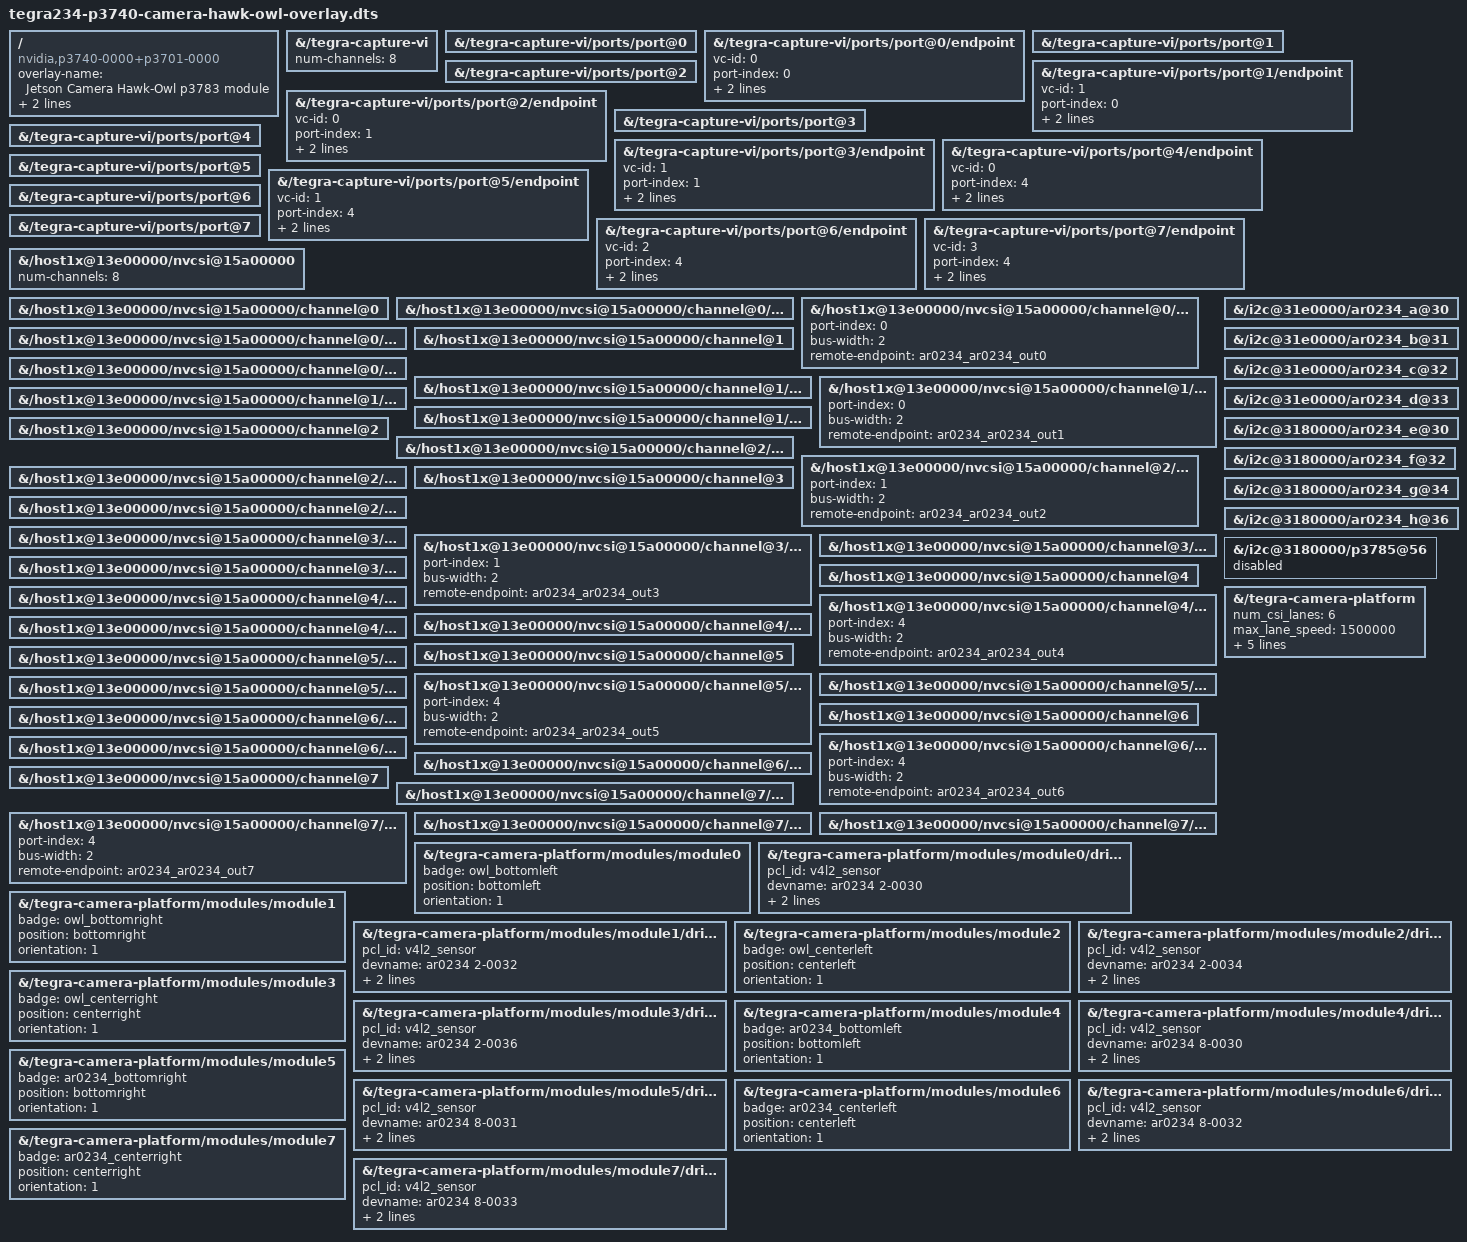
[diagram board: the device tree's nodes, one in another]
/*
 * Copyright (c) 2023, NVIDIA CORPORATION.  All rights reserved.
 *
 * This program is free software; you can redistribute it and/or modify it
 * under the terms and conditions of the GNU General Public License,
 * version 2, as published by the Free Software Foundation.
 *
 * This program is distributed in the hope it will be useful, but WITHOUT
 * ANY WARRANTY; without even the implied warranty of MERCHANTABILITY or
 * FITNESS FOR A PARTICULAR PURPOSE.  See the GNU General Public License for
 * more details.
 *
 * You should have received a copy of the GNU General Public License
 * along with this program.  If not, see <http://www.gnu.org/licenses/>.
 */

/*
 * Device-tree overlay for Hawk & Owl.
 */

/dts-v1/;
/plugin/;

/ {
	overlay-name = "Jetson Camera Hawk-Owl p3783 module";
	jetson-header-name = "Jetson 122pin CSI Connector";
	compatible = "nvidia,p3740-0000+p3701-0000", "nvidia,p3740-0002-b01+p3701-0002";

	/* VI number of channels */
	fragment@0 {
		target-path = "/tegra-capture-vi";
		board_config {
			sw-modules = "kernel";
		};
		__overlay__ {
			num-channels=<8>;
		};
	};

	fragment@1 {
		target-path = "/tegra-capture-vi/ports/port@0";
		board_config {
			sw-modules = "kernel";
		};
		__overlay__ {
			status = "okay";
		};
	};
	fragment@2 {
		target-path = "/tegra-capture-vi/ports/port@0/endpoint";
		board_config {
			sw-modules = "kernel";
		};
		__overlay__ {
			status = "okay";
			vc-id = <0>;
			port-index = <0>;
			bus-width = <2>;
			remote-endpoint = <&ar0234_csi_out0>;
		};
	};
	fragment@3 {
		target-path = "/tegra-capture-vi/ports/port@1";
		board_config {
			sw-modules = "kernel";
		};
		__overlay__ {
			status = "okay";
		};
	};
	fragment@4 {
		target-path = "/tegra-capture-vi/ports/port@1/endpoint";
		board_config {
			sw-modules = "kernel";
		};
		__overlay__ {
			status = "okay";
			vc-id = <1>;
			port-index = <0>;
			bus-width = <2>;
			remote-endpoint = <&ar0234_csi_out1>;
		};
	};
	fragment@5 {
		target-path = "/tegra-capture-vi/ports/port@2";
		board_config {
			sw-modules = "kernel";
		};
		__overlay__ {
			status = "okay";
		};
	};
	fragment@6 {
		target-path = "/tegra-capture-vi/ports/port@2/endpoint";
		board_config {
			sw-modules = "kernel";
		};
		__overlay__ {
			status = "okay";
			vc-id = <0>;
			port-index = <1>;
			bus-width = <2>;
			remote-endpoint = <&ar0234_csi_out2>;
		};
	};
	fragment@7 {
		target-path = "/tegra-capture-vi/ports/port@3";
		board_config {
			sw-modules = "kernel";
		};
		__overlay__ {
			status = "okay";
		};
	};
	fragment@8 {
		target-path = "/tegra-capture-vi/ports/port@3/endpoint";
		board_config {
			sw-modules = "kernel";
		};
		__overlay__ {
			status = "okay";
			vc-id = <1>;
			port-index = <1>;
			bus-width = <2>;
			remote-endpoint = <&ar0234_csi_out3>;
		};
	};
	fragment@9 {
		target-path = "/tegra-capture-vi/ports/port@4";
		board_config {
			sw-modules = "kernel";
		};
		__overlay__ {
			status = "okay";
		};
	};
	fragment@10 {
		target-path = "/tegra-capture-vi/ports/port@4/endpoint";
		board_config {
			sw-modules = "kernel";
		};
		__overlay__ {
			status = "okay";
			vc-id = <0>;
			port-index = <4>;
			bus-width = <2>;
			remote-endpoint = <&ar0234_csi_out4>;
		};
	};
	fragment@11 {
		target-path = "/tegra-capture-vi/ports/port@5";
		board_config {
			sw-modules = "kernel";
		};
		__overlay__ {
			status = "okay";
		};
	};
	fragment@12 {
		target-path = "/tegra-capture-vi/ports/port@5/endpoint";
		board_config {
			sw-modules = "kernel";
		};
		__overlay__ {
			status = "okay";
			vc-id = <1>;
			port-index = <4>;
			bus-width = <2>;
			remote-endpoint = <&ar0234_csi_out5>;
		};
	};
	fragment@13 {
		target-path = "/tegra-capture-vi/ports/port@6";
		board_config {
			sw-modules = "kernel";
		};
		__overlay__ {
			status = "okay";
		};
	};
	fragment@14 {
		target-path = "/tegra-capture-vi/ports/port@6/endpoint";
		board_config {
			sw-modules = "kernel";
		};
		__overlay__ {
			status = "okay";
			vc-id = <2>;
			port-index = <4>;
			bus-width = <2>;
			remote-endpoint = <&ar0234_csi_out6>;
		};
	};
	fragment@15 {
		target-path = "/tegra-capture-vi/ports/port@7";
		board_config {
			sw-modules = "kernel";
		};
		__overlay__ {
			status = "okay";
		};
	};
	fragment@16 {
		target-path = "/tegra-capture-vi/ports/port@7/endpoint";
		board_config {
			sw-modules = "kernel";
		};
		__overlay__ {
			status = "okay";
			vc-id = <3>;
			port-index = <4>;
			bus-width = <2>;
			remote-endpoint = <&ar0234_csi_out7>;
		};
	};
	fragment@17 {
		target-path = "/host1x@13e00000/nvcsi@15a00000";
		board_config {
			sw-modules = "kernel";
		};
		__overlay__ {
			num-channels=<8>;
		};
	};
	fragment@18 {
		target-path = "/host1x@13e00000/nvcsi@15a00000/channel@0";
		board_config {
			sw-modules = "kernel";
		};
		__overlay__ {
			status = "okay";
		};
	};
	fragment@19 {
		target-path = "/host1x@13e00000/nvcsi@15a00000/channel@0/ports/port@0";
		board_config {
			sw-modules = "kernel";
		};
		__overlay__ {
			status = "okay";
		};
	};
	fragment@20 {
		target-path = "/host1x@13e00000/nvcsi@15a00000/channel@0/ports/port@0/endpoint@0";
		board_config {
			sw-modules = "kernel";
		};
		__overlay__ {
			status = "okay";
			port-index = <0>;
			bus-width = <2>;
			remote-endpoint = <&ar0234_ar0234_out0>;
		};
	};
	fragment@21 {
		target-path = "/host1x@13e00000/nvcsi@15a00000/channel@0/ports/port@1";
		board_config {
			sw-modules = "kernel";
		};
		__overlay__ {
			status = "okay";
		};
	};
	fragment@22 {
		target-path = "/host1x@13e00000/nvcsi@15a00000/channel@0/ports/port@1/endpoint@1";
		board_config {
			sw-modules = "kernel";
		};
		__overlay__ {
			status = "okay";
		};
	};
	fragment@23 {
		target-path = "/host1x@13e00000/nvcsi@15a00000/channel@1";
		board_config {
			sw-modules = "kernel";
		};
		__overlay__ {
			status = "okay";
		};
	};
	fragment@24 {
		target-path = "/host1x@13e00000/nvcsi@15a00000/channel@1/ports/port@0";
		board_config {
			sw-modules = "kernel";
		};
		__overlay__ {
			status = "okay";
		};
	};
	fragment@25 {
		target-path = "/host1x@13e00000/nvcsi@15a00000/channel@1/ports/port@0/endpoint@2";
		board_config {
			sw-modules = "kernel";
		};
		__overlay__ {
			status = "okay";
			port-index = <0>;
			bus-width = <2>;
			remote-endpoint = <&ar0234_ar0234_out1>;
		};
	};
	fragment@26 {
		target-path = "/host1x@13e00000/nvcsi@15a00000/channel@1/ports/port@1";
		board_config {
			sw-modules = "kernel";
		};
		__overlay__ {
			status = "okay";
		};
	};
	fragment@27 {
		target-path = "/host1x@13e00000/nvcsi@15a00000/channel@1/ports/port@1/endpoint@3";
		board_config {
			sw-modules = "kernel";
		};
		__overlay__ {
			status = "okay";
		};
	};

	fragment@28 {
		target-path = "/host1x@13e00000/nvcsi@15a00000/channel@2";
		board_config {
			sw-modules = "kernel";
		};
		__overlay__ {
			status = "okay";
		};
	};
	fragment@29 {
		target-path = "/host1x@13e00000/nvcsi@15a00000/channel@2/ports/port@0";
		board_config {
			sw-modules = "kernel";
		};
		__overlay__ {
			status = "okay";
		};
	};
	fragment@30 {
		target-path = "/host1x@13e00000/nvcsi@15a00000/channel@2/ports/port@0/endpoint@4";
		board_config {
			sw-modules = "kernel";
		};
		__overlay__ {
			status = "okay";
			port-index = <1>;
			bus-width = <2>;
			remote-endpoint = <&ar0234_ar0234_out2>;
		};
	};
	fragment@31 {
		target-path = "/host1x@13e00000/nvcsi@15a00000/channel@2/ports/port@1";
		board_config {
			sw-modules = "kernel";
		};
		__overlay__ {
			status = "okay";
		};
	};
	fragment@32 {
		target-path = "/host1x@13e00000/nvcsi@15a00000/channel@2/ports/port@1/endpoint@5";
		board_config {
			sw-modules = "kernel";
		};
		__overlay__ {
			status = "okay";
		};
	};


	fragment@33 {
		target-path = "/host1x@13e00000/nvcsi@15a00000/channel@3";
		board_config {
			sw-modules = "kernel";
		};
		__overlay__ {
			status = "okay";
		};
	};
	fragment@34 {
		target-path = "/host1x@13e00000/nvcsi@15a00000/channel@3/ports/port@0";
		board_config {
			sw-modules = "kernel";
		};
		__overlay__ {
			status = "okay";
		};
	};
	fragment@35 {
		target-path = "/host1x@13e00000/nvcsi@15a00000/channel@3/ports/port@0/endpoint@6";
		board_config {
			sw-modules = "kernel";
		};
		__overlay__ {
			status = "okay";
			port-index = <1>;
			bus-width = <2>;
			remote-endpoint = <&ar0234_ar0234_out3>;
		};
	};
	fragment@36 {
		target-path = "/host1x@13e00000/nvcsi@15a00000/channel@3/ports/port@1";
		board_config {
			sw-modules = "kernel";
		};
		__overlay__ {
			status = "okay";
		};
	};
	fragment@37 {
		target-path = "/host1x@13e00000/nvcsi@15a00000/channel@3/ports/port@1/endpoint@7";
		board_config {
			sw-modules = "kernel";
		};
		__overlay__ {
			status = "okay";
		};
	};


	fragment@38 {
		target-path = "/host1x@13e00000/nvcsi@15a00000/channel@4";
		board_config {
			sw-modules = "kernel";
		};
		__overlay__ {
			status = "okay";
		};
	};
	fragment@39 {
		target-path = "/host1x@13e00000/nvcsi@15a00000/channel@4/ports/port@0";
		board_config {
			sw-modules = "kernel";
		};
		__overlay__ {
			status = "okay";
		};
	};
	fragment@40 {
		target-path = "/host1x@13e00000/nvcsi@15a00000/channel@4/ports/port@0/endpoint@8";
		board_config {
			sw-modules = "kernel";
		};
		__overlay__ {
			status = "okay";
			port-index = <4>;
			bus-width = <2>;
			remote-endpoint = <&ar0234_ar0234_out4>;
		};
	};
	fragment@41 {
		target-path = "/host1x@13e00000/nvcsi@15a00000/channel@4/ports/port@1";
		board_config {
			sw-modules = "kernel";
		};
		__overlay__ {
			status = "okay";
		};
	};
	fragment@42 {
		target-path = "/host1x@13e00000/nvcsi@15a00000/channel@4/ports/port@1/endpoint@9";
		board_config {
			sw-modules = "kernel";
		};
		__overlay__ {
			status = "okay";
		};
	};


	fragment@43 {
		target-path = "/host1x@13e00000/nvcsi@15a00000/channel@5";
		board_config {
			sw-modules = "kernel";
		};
		__overlay__ {
			status = "okay";
		};
	};
	fragment@44 {
		target-path = "/host1x@13e00000/nvcsi@15a00000/channel@5/ports/port@0";
		board_config {
			sw-modules = "kernel";
		};
		__overlay__ {
			status = "okay";
		};
	};
	fragment@45 {
		target-path = "/host1x@13e00000/nvcsi@15a00000/channel@5/ports/port@0/endpoint@10";
		board_config {
			sw-modules = "kernel";
		};
		__overlay__ {
			status = "okay";
			port-index = <4>;
			bus-width = <2>;
			remote-endpoint = <&ar0234_ar0234_out5>;
		};
	};
	fragment@46 {
		target-path = "/host1x@13e00000/nvcsi@15a00000/channel@5/ports/port@1";
		board_config {
			sw-modules = "kernel";
		};
		__overlay__ {
			status = "okay";
		};
	};
	fragment@47 {
		target-path = "/host1x@13e00000/nvcsi@15a00000/channel@5/ports/port@1/endpoint@11";
		board_config {
			sw-modules = "kernel";
		};
		__overlay__ {
			status = "okay";
		};
	};

	fragment@48 {
		target-path = "/host1x@13e00000/nvcsi@15a00000/channel@6";
		board_config {
			sw-modules = "kernel";
		};
		__overlay__ {
			status = "okay";
		};
	};
	fragment@49 {
		target-path = "/host1x@13e00000/nvcsi@15a00000/channel@6/ports/port@0";
		board_config {
			sw-modules = "kernel";
		};
		__overlay__ {
			status = "okay";
		};
	};
	fragment@50 {
		target-path = "/host1x@13e00000/nvcsi@15a00000/channel@6/ports/port@0/endpoint@12";
		board_config {
			sw-modules = "kernel";
		};
		__overlay__ {
			status = "okay";
			port-index = <4>;
			bus-width = <2>;
			remote-endpoint = <&ar0234_ar0234_out6>;
		};
	};
	fragment@51 {
		target-path = "/host1x@13e00000/nvcsi@15a00000/channel@6/ports/port@1";
		board_config {
			sw-modules = "kernel";
		};
		__overlay__ {
			status = "okay";
		};
	};
	fragment@52 {
		target-path = "/host1x@13e00000/nvcsi@15a00000/channel@6/ports/port@1/endpoint@13";
		board_config {
			sw-modules = "kernel";
		};
		__overlay__ {
			status = "okay";
		};
	};


	fragment@53 {
		target-path = "/host1x@13e00000/nvcsi@15a00000/channel@7";
		board_config {
			sw-modules = "kernel";
		};
		__overlay__ {
			status = "okay";
		};
	};
	fragment@54 {
		target-path = "/host1x@13e00000/nvcsi@15a00000/channel@7/ports/port@0";
		board_config {
			sw-modules = "kernel";
		};
		__overlay__ {
			status = "okay";
		};
	};
	fragment@55 {
		target-path = "/host1x@13e00000/nvcsi@15a00000/channel@7/ports/port@0/endpoint@14";
		board_config {
			sw-modules = "kernel";
		};
		__overlay__ {
			status = "okay";
			port-index = <4>;
			bus-width = <2>;
			remote-endpoint = <&ar0234_ar0234_out7>;
		};
	};
	fragment@56 {
		target-path = "/host1x@13e00000/nvcsi@15a00000/channel@7/ports/port@1";
		board_config {
			sw-modules = "kernel";
		};
		__overlay__ {
			status = "okay";
		};
	};
	fragment@57 {
		target-path = "/host1x@13e00000/nvcsi@15a00000/channel@7/ports/port@1/endpoint@15";
		board_config {
			sw-modules = "kernel";
		};
		__overlay__ {
			status = "okay";
		};
	};

	fragment@58 {
		target-path = "/i2c@31e0000/ar0234_a@30";
		board_config {
			sw-modules = "kernel";
		};
		__overlay__ {
			status = "okay";
		};
	};
	fragment@59 {
		target-path = "/i2c@31e0000/ar0234_b@31";
		board_config {
			sw-modules = "kernel";
		};
		__overlay__ {
			status = "okay";
		};
	};
	fragment@60 {
		target-path = "/i2c@31e0000/ar0234_c@32";
		board_config {
			sw-modules = "kernel";
		};
		__overlay__ {
			status = "okay";
		};
	};
	fragment@61 {
		target-path = "/i2c@31e0000/ar0234_d@33";
		board_config {
			sw-modules = "kernel";
		};
		__overlay__ {
			status = "okay";
		};
	};
	fragment@62 {
		target-path = "/i2c@3180000/ar0234_e@30";
		board_config {
			sw-modules = "kernel";
		};
		__overlay__ {
			status = "okay";
		};
	};
	fragment@63 {
		target-path = "/i2c@3180000/ar0234_f@32";
		board_config {
			sw-modules = "kernel";
		};
		__overlay__ {
			status = "okay";
		};
	};
	fragment@64 {
		target-path = "/i2c@3180000/ar0234_g@34";
		board_config {
			sw-modules = "kernel";
		};
		__overlay__ {
			status = "okay";
		};
	};
	fragment@65 {
		target-path = "/i2c@3180000/ar0234_h@36";
		board_config {
			sw-modules = "kernel";
		};
		__overlay__ {
			status = "okay";
		};
	};

	fragment@66 {
		target-path = "/i2c@3180000/p3785@56";
		board_config {
			sw-modules = "kernel";
		};
		__overlay__ {
			status = "disbaled";
		};
	};

	fragment@67 {
		target-path = "/tegra-camera-platform";
		board_config {
			sw-modules = "kernel";
		};
		__overlay__ {
			num_csi_lanes = <6>;
			max_lane_speed = <1500000>;
			min_bits_per_pixel = <10>;
			vi_peak_byte_per_pixel = <2>;
			vi_bw_margin_pct = <25>;
			isp_peak_byte_per_pixel = <5>;
			isp_bw_margin_pct = <25>;
		};
	};

	fragment@68 {
		target-path = "/tegra-camera-platform/modules/module0";
		board_config {
			sw-modules = "kernel";
		};
		__overlay__ {
			status = "okay";
			badge = "owl_bottomleft";
			position = "bottomleft";
			orientation = "1";
		};
	};

	fragment@69 {
		target-path = "/tegra-camera-platform/modules/module0/drivernode0";
		board_config {
			sw-modules = "kernel";
		};
		__overlay__ {
			status = "okay";
			pcl_id = "v4l2_sensor";
			devname = "ar0234 2-0030";
			proc-device-tree = "/proc/device-tree/i2c@3180000/ar0234_e@30";
		};
	};

	fragment@70 {
		target-path = "/tegra-camera-platform/modules/module1";
		board_config {
			sw-modules = "kernel";
		};
		__overlay__ {
			status = "okay";
			badge = "owl_bottomright";
			position = "bottomright";
			orientation = "1";
		};
	};

	fragment@71 {
		target-path = "/tegra-camera-platform/modules/module1/drivernode0";
		board_config {
			sw-modules = "kernel";
		};
		__overlay__ {
			status = "okay";
			pcl_id = "v4l2_sensor";
			devname = "ar0234 2-0032";
			proc-device-tree = "/proc/device-tree/i2c@3180000/ar0234_f@32";
		};
	};
	fragment@72 {
		target-path = "/tegra-camera-platform/modules/module2";
		board_config {
			sw-modules = "kernel";
		};
		__overlay__ {
			status = "okay";
			badge = "owl_centerleft";
			position = "centerleft";
			orientation = "1";
		};
	};

	fragment@73 {
		target-path = "/tegra-camera-platform/modules/module2/drivernode0";
		board_config {
			sw-modules = "kernel";
		};
		__overlay__ {
			status = "okay";
			pcl_id = "v4l2_sensor";
			devname = "ar0234 2-0034";
			proc-device-tree = "/proc/device-tree/i2c@3180000/ar0234_g@34";
		};
	};
	fragment@74 {
		target-path = "/tegra-camera-platform/modules/module3";
		board_config {
			sw-modules = "kernel";
		};
		__overlay__ {
			status = "okay";
			badge = "owl_centerright";
			position = "centerright";
			orientation = "1";
		};
	};

	fragment@75 {
		target-path = "/tegra-camera-platform/modules/module3/drivernode0";
		board_config {
			sw-modules = "kernel";
		};
		__overlay__ {
			status = "okay";
			pcl_id = "v4l2_sensor";
			devname = "ar0234 2-0036";
			proc-device-tree = "/proc/device-tree/i2c@3180000/ar0234_h@36";
		};
	};
	fragment@76 {
		target-path = "/tegra-camera-platform/modules/module4";
		board_config {
			sw-modules = "kernel";
		};
		__overlay__ {
			status = "okay";
			badge = "ar0234_bottomleft";
			position = "bottomleft";
			orientation = "1";
		};
	};

	fragment@77 {
		target-path = "/tegra-camera-platform/modules/module4/drivernode0";
		board_config {
			sw-modules = "kernel";
		};
		__overlay__ {
			status = "okay";
			pcl_id = "v4l2_sensor";
			devname = "ar0234 8-0030";
			proc-device-tree = "/proc/device-tree/i2c@31e0000/ar0234_a@30";
		};
	};
	fragment@78 {
		target-path = "/tegra-camera-platform/modules/module5";
		board_config {
			sw-modules = "kernel";
		};
		__overlay__ {
			status = "okay";
			badge = "ar0234_bottomright";
			position = "bottomright";
			orientation = "1";
		};
	};

	fragment@79 {
		target-path = "/tegra-camera-platform/modules/module5/drivernode0";
		board_config {
			sw-modules = "kernel";
		};
		__overlay__ {
			status = "okay";
			pcl_id = "v4l2_sensor";
			devname = "ar0234 8-0031";
			proc-device-tree = "/proc/device-tree/i2c@31e0000/ar0234_b@31";
		};
	};
	fragment@80 {
		target-path = "/tegra-camera-platform/modules/module6";
		board_config {
			sw-modules = "kernel";
		};
		__overlay__ {
			status = "okay";
			badge = "ar0234_centerleft";
			position = "centerleft";
			orientation = "1";
		};
	};

	fragment@81 {
		target-path = "/tegra-camera-platform/modules/module6/drivernode0";
		board_config {
			sw-modules = "kernel";
		};
		__overlay__ {
			status = "okay";
			pcl_id = "v4l2_sensor";
			devname = "ar0234 8-0032";
			proc-device-tree = "/proc/device-tree/i2c@31e0000/ar0234_c@32";
		};
	};
	fragment@82 {
		target-path = "/tegra-camera-platform/modules/module7";
		board_config {
			sw-modules = "kernel";
		};
		__overlay__ {
			status = "okay";
			badge = "ar0234_centerright";
			position = "centerright";
			orientation = "1";
		};
	};

	fragment@83 {
		target-path = "/tegra-camera-platform/modules/module7/drivernode0";
		board_config {
			sw-modules = "kernel";
		};
		__overlay__ {
			status = "okay";
			pcl_id = "v4l2_sensor";
			devname = "ar0234 8-0033";
			proc-device-tree = "/proc/device-tree/i2c@31e0000/ar0234_d@33";
		};
	};
};
